CM_ "AUTOGENERATED FILE, DO NOT EDIT";

CM_ "hyundai_kia_denso_front_radar.dbc starts here";

VERSION ""

NS_ :

BS_:

BU_: XXX

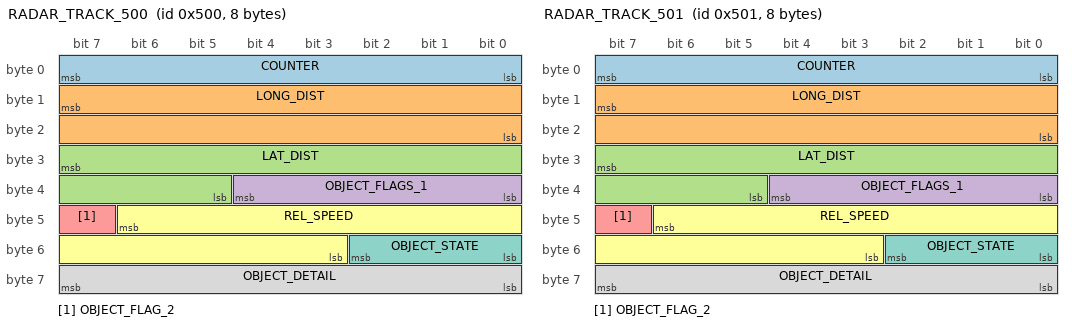
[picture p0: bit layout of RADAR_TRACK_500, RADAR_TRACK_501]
BO_ 1280 RADAR_TRACK_500: 8 RADAR
 SG_ COUNTER : 7|8@0+ (1,0) [0|255] "" XXX
 SG_ LONG_DIST : 15|16@0+ (0.00625,0) [0|409.59375] "m" XXX
 SG_ LAT_DIST : 31|11@0- (0.0625,0) [-64|63.9375] "m" XXX
 SG_ OBJECT_FLAGS_1 : 36|5@0+ (1,0) [0|31] "" XXX
 SG_ OBJECT_FLAG_2 : 47|1@0+ (1,0) [0|1] "" XXX
 SG_ REL_SPEED : 46|12@0- (0.015625,0) [-32|31.984375] "m/s" XXX
 SG_ OBJECT_STATE : 50|3@0+ (1,0) [0|7] "" XXX
 SG_ OBJECT_DETAIL : 63|8@0+ (1,0) [0|255] "" XXX

BO_ 1281 RADAR_TRACK_501: 8 RADAR
 SG_ COUNTER : 7|8@0+ (1,0) [0|255] "" XXX
 SG_ LONG_DIST : 15|16@0+ (0.00625,0) [0|409.59375] "m" XXX
 SG_ LAT_DIST : 31|11@0- (0.0625,0) [-64|63.9375] "m" XXX
 SG_ OBJECT_FLAGS_1 : 36|5@0+ (1,0) [0|31] "" XXX
 SG_ OBJECT_FLAG_2 : 47|1@0+ (1,0) [0|1] "" XXX
 SG_ REL_SPEED : 46|12@0- (0.015625,0) [-32|31.984375] "m/s" XXX
 SG_ OBJECT_STATE : 50|3@0+ (1,0) [0|7] "" XXX
 SG_ OBJECT_DETAIL : 63|8@0+ (1,0) [0|255] "" XXX

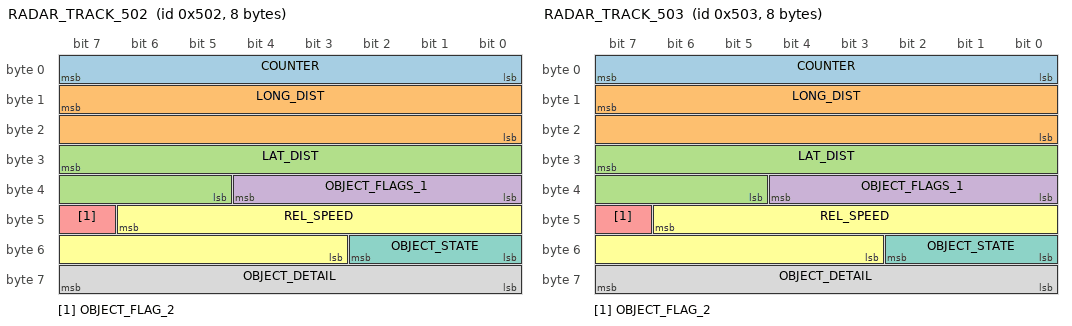
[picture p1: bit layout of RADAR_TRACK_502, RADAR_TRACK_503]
BO_ 1282 RADAR_TRACK_502: 8 RADAR
 SG_ COUNTER : 7|8@0+ (1,0) [0|255] "" XXX
 SG_ LONG_DIST : 15|16@0+ (0.00625,0) [0|409.59375] "m" XXX
 SG_ LAT_DIST : 31|11@0- (0.0625,0) [-64|63.9375] "m" XXX
 SG_ OBJECT_FLAGS_1 : 36|5@0+ (1,0) [0|31] "" XXX
 SG_ OBJECT_FLAG_2 : 47|1@0+ (1,0) [0|1] "" XXX
 SG_ REL_SPEED : 46|12@0- (0.015625,0) [-32|31.984375] "m/s" XXX
 SG_ OBJECT_STATE : 50|3@0+ (1,0) [0|7] "" XXX
 SG_ OBJECT_DETAIL : 63|8@0+ (1,0) [0|255] "" XXX

BO_ 1283 RADAR_TRACK_503: 8 RADAR
 SG_ COUNTER : 7|8@0+ (1,0) [0|255] "" XXX
 SG_ LONG_DIST : 15|16@0+ (0.00625,0) [0|409.59375] "m" XXX
 SG_ LAT_DIST : 31|11@0- (0.0625,0) [-64|63.9375] "m" XXX
 SG_ OBJECT_FLAGS_1 : 36|5@0+ (1,0) [0|31] "" XXX
 SG_ OBJECT_FLAG_2 : 47|1@0+ (1,0) [0|1] "" XXX
 SG_ REL_SPEED : 46|12@0- (0.015625,0) [-32|31.984375] "m/s" XXX
 SG_ OBJECT_STATE : 50|3@0+ (1,0) [0|7] "" XXX
 SG_ OBJECT_DETAIL : 63|8@0+ (1,0) [0|255] "" XXX

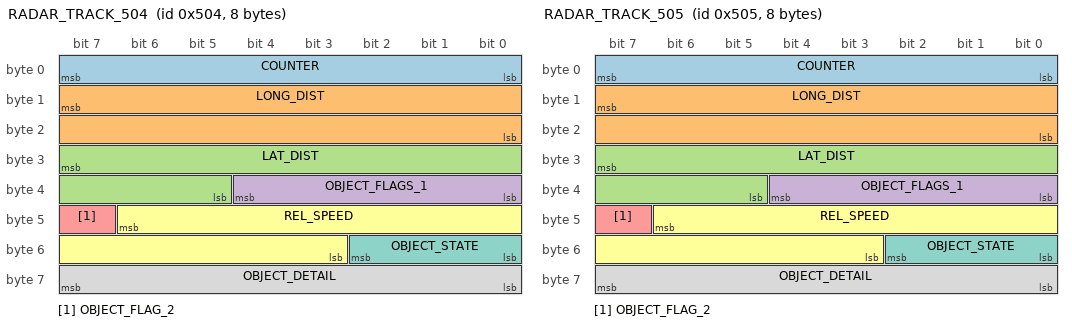
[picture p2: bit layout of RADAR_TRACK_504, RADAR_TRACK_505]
BO_ 1284 RADAR_TRACK_504: 8 RADAR
 SG_ COUNTER : 7|8@0+ (1,0) [0|255] "" XXX
 SG_ LONG_DIST : 15|16@0+ (0.00625,0) [0|409.59375] "m" XXX
 SG_ LAT_DIST : 31|11@0- (0.0625,0) [-64|63.9375] "m" XXX
 SG_ OBJECT_FLAGS_1 : 36|5@0+ (1,0) [0|31] "" XXX
 SG_ OBJECT_FLAG_2 : 47|1@0+ (1,0) [0|1] "" XXX
 SG_ REL_SPEED : 46|12@0- (0.015625,0) [-32|31.984375] "m/s" XXX
 SG_ OBJECT_STATE : 50|3@0+ (1,0) [0|7] "" XXX
 SG_ OBJECT_DETAIL : 63|8@0+ (1,0) [0|255] "" XXX

BO_ 1285 RADAR_TRACK_505: 8 RADAR
 SG_ COUNTER : 7|8@0+ (1,0) [0|255] "" XXX
 SG_ LONG_DIST : 15|16@0+ (0.00625,0) [0|409.59375] "m" XXX
 SG_ LAT_DIST : 31|11@0- (0.0625,0) [-64|63.9375] "m" XXX
 SG_ OBJECT_FLAGS_1 : 36|5@0+ (1,0) [0|31] "" XXX
 SG_ OBJECT_FLAG_2 : 47|1@0+ (1,0) [0|1] "" XXX
 SG_ REL_SPEED : 46|12@0- (0.015625,0) [-32|31.984375] "m/s" XXX
 SG_ OBJECT_STATE : 50|3@0+ (1,0) [0|7] "" XXX
 SG_ OBJECT_DETAIL : 63|8@0+ (1,0) [0|255] "" XXX

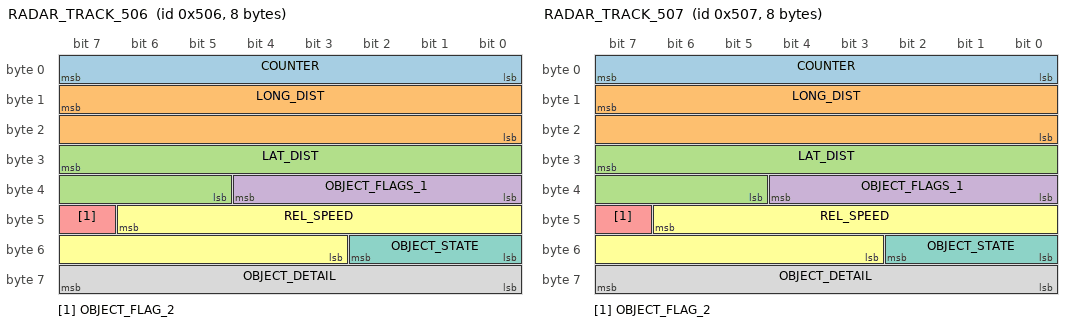
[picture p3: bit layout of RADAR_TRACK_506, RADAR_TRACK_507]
BO_ 1286 RADAR_TRACK_506: 8 RADAR
 SG_ COUNTER : 7|8@0+ (1,0) [0|255] "" XXX
 SG_ LONG_DIST : 15|16@0+ (0.00625,0) [0|409.59375] "m" XXX
 SG_ LAT_DIST : 31|11@0- (0.0625,0) [-64|63.9375] "m" XXX
 SG_ OBJECT_FLAGS_1 : 36|5@0+ (1,0) [0|31] "" XXX
 SG_ OBJECT_FLAG_2 : 47|1@0+ (1,0) [0|1] "" XXX
 SG_ REL_SPEED : 46|12@0- (0.015625,0) [-32|31.984375] "m/s" XXX
 SG_ OBJECT_STATE : 50|3@0+ (1,0) [0|7] "" XXX
 SG_ OBJECT_DETAIL : 63|8@0+ (1,0) [0|255] "" XXX

BO_ 1287 RADAR_TRACK_507: 8 RADAR
 SG_ COUNTER : 7|8@0+ (1,0) [0|255] "" XXX
 SG_ LONG_DIST : 15|16@0+ (0.00625,0) [0|409.59375] "m" XXX
 SG_ LAT_DIST : 31|11@0- (0.0625,0) [-64|63.9375] "m" XXX
 SG_ OBJECT_FLAGS_1 : 36|5@0+ (1,0) [0|31] "" XXX
 SG_ OBJECT_FLAG_2 : 47|1@0+ (1,0) [0|1] "" XXX
 SG_ REL_SPEED : 46|12@0- (0.015625,0) [-32|31.984375] "m/s" XXX
 SG_ OBJECT_STATE : 50|3@0+ (1,0) [0|7] "" XXX
 SG_ OBJECT_DETAIL : 63|8@0+ (1,0) [0|255] "" XXX
